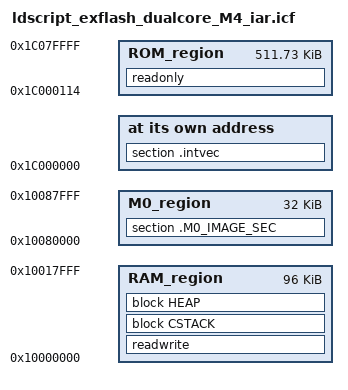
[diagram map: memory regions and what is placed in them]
/*###ICF### Section handled by ICF editor, don't touch! ****/
/*-Editor annotation file-*/
/* IcfEditorFile="$TOOLKIT_DIR$\config\ide\IcfEditor\cortex_v1_0.xml" */
/*-Specials-*/
define symbol __ICFEDIT_intvec_start__ = 0x1C000000;
/*-Memory Regions-*/
define symbol __ICFEDIT_region_ROM_start__ = 0x1C000114;
define symbol __ICFEDIT_region_ROM_end__   = 0x1C07FFFF;
define symbol __ICFEDIT_region_RAM_start__ = 0x10000000;
define symbol __ICFEDIT_region_RAM_end__   = 0x10017FFF;
/*-Sizes-*/
define symbol __ICFEDIT_size_cstack__ = 0x400;
define symbol __ICFEDIT_size_heap__   = 0x200;
/**** End of ICF editor section. ###ICF###*/

/* define symbol __CRP_start__   = 0x000002FC; */
/* define symbol __CRP_end__     = 0x000002FF; */

define symbol M0_region_start__ = 0x10080000;
define symbol M0_region_end__   = 0x10087FFF;

define memory mem with size = 4G;
define region ROM_region   = mem:[from __ICFEDIT_region_ROM_start__   to __ICFEDIT_region_ROM_end__];
define region RAM_region   = mem:[from __ICFEDIT_region_RAM_start__   to __ICFEDIT_region_RAM_end__];
define region M0_region    = mem:[from M0_region_start__   to M0_region_end__];

define block CSTACK    with alignment = 8, size = __ICFEDIT_size_cstack__   { };
define block HEAP      with alignment = 8, size = __ICFEDIT_size_heap__     { };

initialize by copy with packing = zeros { readwrite, ro object lpc43xx_cgu.o, ro object lpc43xx_emc.o, ro object Hitex_Fast_Startup.o };

do not initialize  { section .noinit };
initialize by copy { section .M0_IMAGE_SEC };

place at start of ROM_region { block StartupCode with fixed order { ro object cstartup_M.o, ro object init.o, ro object cmain.o } };

place at address mem:__ICFEDIT_intvec_start__ { section .intvec };

place in ROM_region     { readonly };
place in RAM_region     { readwrite,
                          block CSTACK, block HEAP };

place in M0_region      { section .M0_IMAGE_SEC };

/* place in CRP_region  { section .crp}; */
